# ATSAMD51P register map
Vendor: Microchip Technology Inc.; Series: SAMD51; File version: A
CPU: CM4 r0p1, little endian, MPU, FPU, 3 interrupt priority bits, 137 interrupts
Registers are 32-bit, read-write, reset 0x0 unless marked. A register's access mark holds for its fields unless they carry their own. Offsets are from the block's base; [hi:lo] are bit positions; {n}, {i} and the like mark numbered series; 'fields as' and 'values as' point back to an identical list.

## PCC — Parallel Capture Controller
Base 0x43002C00; register names take the prefix PCC_
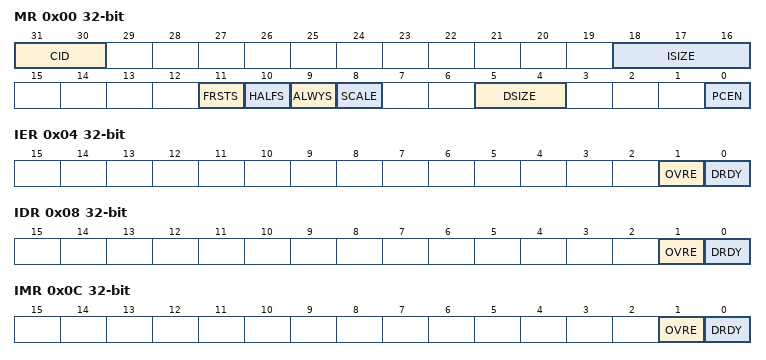
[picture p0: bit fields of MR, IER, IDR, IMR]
0x00 MR — Mode Register
  [31:30] CID — Clear If Disabled
  [18:16] ISIZE — Input Data Size
  [11] FRSTS — First sample
  [10] HALFS — Half Sampling
  [9] ALWYS — Always Sampling
  [8] SCALE — Scale data
  [5:4] DSIZE — Data size
  [0] PCEN — Parallel Capture Enable
0x04 IER wo — Interrupt Enable Register
  [1] OVRE — Overrun Error Interrupt Enable
  [0] DRDY — Data Ready Interrupt Enable
0x08 IDR wo — Interrupt Disable Register
  [1] OVRE — Overrun Error Interrupt Disable
  [0] DRDY — Data Ready Interrupt Disable
0x0C IMR ro — Interrupt Mask Register
  [1] OVRE — Overrun Error Interrupt Mask
  [0] DRDY — Data Ready Interrupt Mask
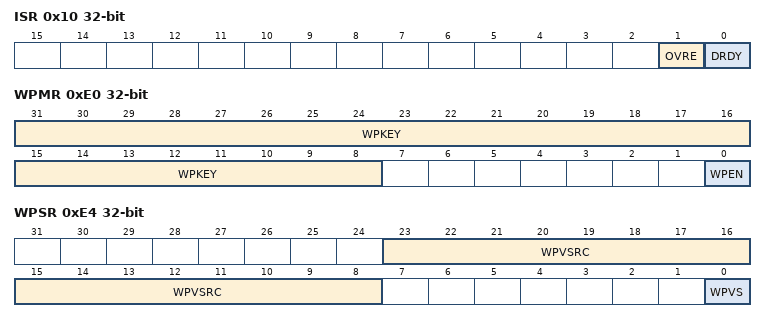
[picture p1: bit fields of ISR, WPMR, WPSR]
0x10 ISR ro — Interrupt Status Register
  [1] OVRE — Overrun Error Interrupt Status
  [0] DRDY — Data Ready Interrupt Status
0x14 RHR ro — Reception Holding Register
  [31:0] RDATA — Reception Data
0xE0 WPMR — Write Protection Mode Register
  [31:8] WPKEY — Write Protection Key
  [0] WPEN — Write Protection Enable
0xE4 WPSR ro — Write Protection Status Register
  [23:8] WPVSRC — Write Protection Violation Status
  [0] WPVS — Write Protection Violation Source

## PM — Power Manager
Base 0x40000400; register names take the prefix PM_
0x00 CTRLA 8-bit — Control A
  [2] IORET — I/O Retention
0x01 SLEEPCFG 8-bit reset 0x2 — Sleep Configuration
  [2:0] SLEEPMODE
    0=IDLE0 (CPU clock is OFF); 1=IDLE1 (AHB clock is OFF); 2=IDLE2 (APB clock are OFF); 4=STANDBY (All Clocks are OFF); 5=HIBERNATE (Backup domain is ON as well as some PDRAMs); 6=BACKUP (Only Backup domain is powered ON); 7=OFF (All power domains are powered OFF)
0x04 INTENCLR 8-bit — Interrupt Enable Clear
  [0] SLEEPRDY wo — Sleep Mode Entry Ready Enable
0x05 INTENSET 8-bit — Interrupt Enable Set
  [0] SLEEPRDY — Sleep Mode Entry Ready Enable
0x06 INTFLAG 8-bit — Interrupt Flag Status and Clear
  [0] SLEEPRDY — Sleep Mode Entry Ready
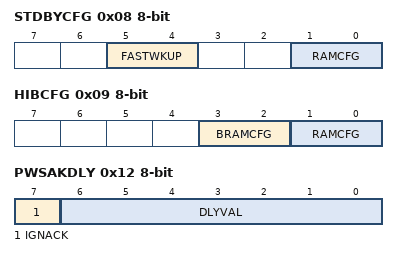
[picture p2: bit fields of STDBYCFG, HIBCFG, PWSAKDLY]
0x08 STDBYCFG 8-bit — Standby Configuration
  [5:4] FASTWKUP — Fast Wakeup
  [1:0] RAMCFG — Ram Configuration
    0=RET (All the RAMs are retained); 1=PARTIAL (Only the first 32K bytes are retained); 2=OFF (All the RAMs are OFF)
0x09 HIBCFG 8-bit — Hibernate Configuration
  [3:2] BRAMCFG — Backup Ram Configuration
  [1:0] RAMCFG — Ram Configuration
0x0A BKUPCFG 8-bit — Backup Configuration
  [1:0] BRAMCFG — Ram Configuration
0x12 PWSAKDLY 8-bit — Power Switch Acknowledge Delay
  [7] IGNACK — Ignore Acknowledge
  [6:0] DLYVAL — Delay Value

## PORT — Port Module
Base 0x41008000; register names take the prefix PORT_
{0x0+0x80*i} DIR{i} (i=0..3) — Data Direction
  [31:0] DIR — Port Data Direction
{0x4+0x80*i} DIRCLR{i} (i=0..3) — Data Direction Clear
  [31:0] DIRCLR — Port Data Direction Clear
{0x8+0x80*i} DIRSET{i} (i=0..3) — Data Direction Set
  [31:0] DIRSET — Port Data Direction Set
{0xC+0x80*i} DIRTGL{i} (i=0..3) — Data Direction Toggle
  [31:0] DIRTGL — Port Data Direction Toggle
{0x10+0x80*i} OUT{i} (i=0..3) — Data Output Value
  [31:0] OUT — PORT Data Output Value
{0x14+0x80*i} OUTCLR{i} (i=0..3) — Data Output Value Clear
  [31:0] OUTCLR — PORT Data Output Value Clear
{0x18+0x80*i} OUTSET{i} (i=0..3) — Data Output Value Set
  [31:0] OUTSET — PORT Data Output Value Set
{0x1C+0x80*i} OUTTGL{i} (i=0..3) — Data Output Value Toggle
  [31:0] OUTTGL — PORT Data Output Value Toggle
{0x20+0x80*i} IN{i} (i=0..3) ro — Data Input Value
  [31:0] IN — PORT Data Input Value
{0x24+0x80*i} CTRL{i} (i=0..3) — Control
  [31:0] SAMPLING wo — Input Sampling Mode
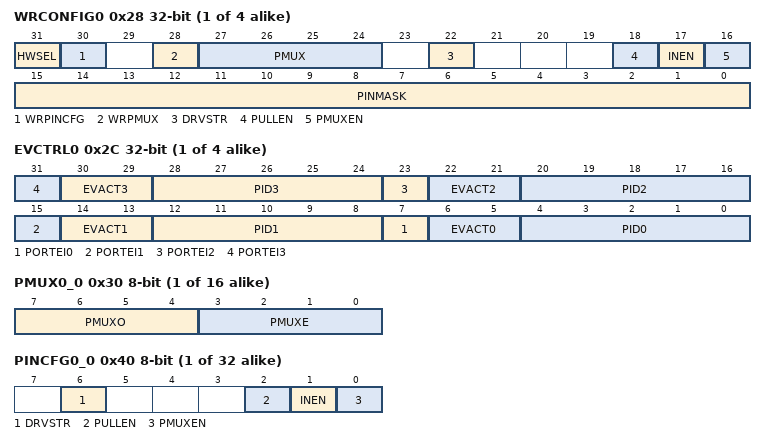
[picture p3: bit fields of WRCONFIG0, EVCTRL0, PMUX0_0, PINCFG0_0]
{0x28+0x80*i} WRCONFIG{i} (i=0..3) wo — Write Configuration
  [31] HWSEL — Half-Word Select
  [30] WRPINCFG — Write PINCFG
  [28] WRPMUX — Write PMUX
  [27:24] PMUX — Peripheral Multiplexing
  [22] DRVSTR — Output Driver Strength Selection
  [18] PULLEN — Pull Enable
  [17] INEN — Input Enable
  [16] PMUXEN — Peripheral Multiplexer Enable
  [15:0] PINMASK — Pin Mask for Multiple Pin Configuration
{0x2C+0x80*i} EVCTRL{i} (i=0..3) — Event Input Control
  [8n+7] PORTEI{n} (n=0..3) — PORT Event Input Enable {n}
  [30:29] EVACT3 — PORT Event Action 3
  [8n+4:8n] PID{n} (n=0..3) — PORT Event Pin Identifier {n}
  [22:21] EVACT2 — PORT Event Action 2
  [14:13] EVACT1 — PORT Event Action 1
  [6:5] EVACT0 — PORT Event Action 0
    0=OUT (Event output to pin); 1=SET (Set output register of pin on event); 2=CLR (Clear output register of pin on event); 3=TGL (Toggle output register of pin on event)
{0x30+i} PMUX0_{i} (i=0..15) 8-bit — Peripheral Multiplexing - Group 0
  [7:4] PMUXO — Peripheral Multiplexing for Odd-Numbered Pin
  [3:0] PMUXE — Peripheral Multiplexing for Even-Numbered Pin
{0x40+i} PINCFG0_{i} (i=0..31) 8-bit — Pin Configuration - Group 0
  [6] DRVSTR — Output Driver Strength Selection
  [2] PULLEN — Pull Enable
  [1] INEN — Input Enable
  [0] PMUXEN — Peripheral Multiplexer Enable
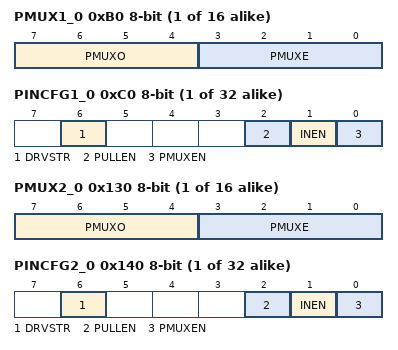
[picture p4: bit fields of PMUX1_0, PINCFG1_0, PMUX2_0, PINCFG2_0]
{0xB0+i} PMUX1_{i} (i=0..15) 8-bit — Peripheral Multiplexing - Group 1
  fields as PMUX0_0
{0xC0+i} PINCFG1_{i} (i=0..31) 8-bit — Pin Configuration - Group 1
  fields as PINCFG0_0
{0x130+i} PMUX2_{i} (i=0..15) 8-bit — Peripheral Multiplexing - Group 2
  fields as PMUX0_0
{0x140+i} PINCFG2_{i} (i=0..31) 8-bit — Pin Configuration - Group 2
  fields as PINCFG0_0
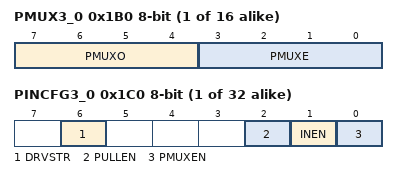
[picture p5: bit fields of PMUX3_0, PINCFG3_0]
{0x1B0+i} PMUX3_{i} (i=0..15) 8-bit — Peripheral Multiplexing - Group 3
  fields as PMUX0_0
{0x1C0+i} PINCFG3_{i} (i=0..31) 8-bit — Pin Configuration - Group 3
  fields as PINCFG0_0

## RAMECC
Base 0x41020000; register names take the prefix RAMECC_
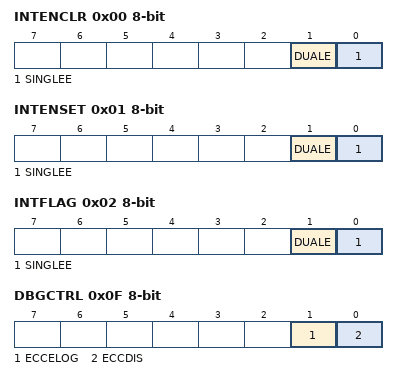
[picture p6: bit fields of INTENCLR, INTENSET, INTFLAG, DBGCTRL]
0x00 INTENCLR 8-bit — Interrupt Enable Clear
  [1] DUALE — Dual Bit ECC Error Interrupt Enable Clear
  [0] SINGLEE — Single Bit ECC Error Interrupt Enable Clear
0x01 INTENSET 8-bit — Interrupt Enable Set
  [1] DUALE — Dual Bit ECC Error Interrupt Enable Set
  [0] SINGLEE — Single Bit ECC Error Interrupt Enable Set
0x02 INTFLAG 8-bit — Interrupt Flag
  [1] DUALE — Dual Bit ECC Error Interrupt
  [0] SINGLEE — Single Bit ECC Error Interrupt
0x03 STATUS 8-bit ro
  [0] ECCDIS — ECC Disable
0x04 ERRADDR ro — Error Address
  [16:0] ERRADDR
0x0F DBGCTRL 8-bit — Debug Control
  [1] ECCELOG — ECC Error Log
  [0] ECCDIS — ECC Disable

## RSTC — Reset Controller
Base 0x40000C00; register names take the prefix RSTC_
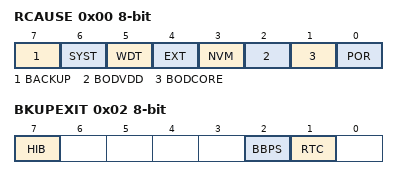
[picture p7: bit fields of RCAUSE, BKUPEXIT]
0x00 RCAUSE 8-bit ro — Reset Cause
  [7] BACKUP — Backup Reset
  [6] SYST — System Reset Request
  [5] WDT — Watchdog Reset
  [4] EXT — External Reset
  [3] NVM — NVM Reset
  [2] BODVDD — Brown Out VDD Detector Reset
  [1] BODCORE — Brown Out CORE Detector Reset
  [0] POR — Power On Reset
0x02 BKUPEXIT 8-bit ro — Backup Exit Source
  [7] HIB — Hibernate
  [2] BBPS — Battery Backup Power Switch
  [1] RTC — Real Timer Counter Interrupt

## TRNG — True Random Generator
Base 0x42002800; register names take the prefix TRNG_
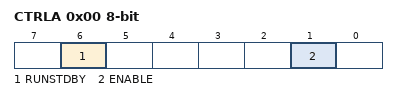
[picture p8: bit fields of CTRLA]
0x00 CTRLA 8-bit — Control A
  [6] RUNSTDBY — Run in Standby
  [1] ENABLE
0x04 EVCTRL 8-bit — Event Control
  [0] DATARDYEO — Data Ready Event Output
0x08 INTENCLR 8-bit — Interrupt Enable Clear
  [0] DATARDY — Data Ready Interrupt Enable
0x09 INTENSET 8-bit — Interrupt Enable Set
  [0] DATARDY — Data Ready Interrupt Enable
0x0A INTFLAG 8-bit — Interrupt Flag Status and Clear
  [0] DATARDY — Data Ready Interrupt Flag
0x20 DATA ro — Output Data

## WDT — Watchdog Timer
Base 0x40002000; register names take the prefix WDT_
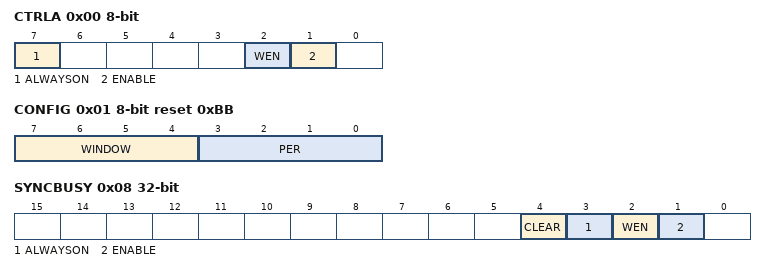
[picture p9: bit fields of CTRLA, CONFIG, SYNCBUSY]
0x00 CTRLA 8-bit — Control
  [7] ALWAYSON
  [2] WEN — Watchdog Timer Window Mode Enable
  [1] ENABLE
0x01 CONFIG 8-bit reset 0xBB — Configuration
  [7:4] WINDOW — Window Mode Time-Out Period
    0=CYC8 (8 clock cycles); 1=CYC16 (16 clock cycles); 2=CYC32 (32 clock cycles); 3=CYC64 (64 clock cycles); 4=CYC128 (128 clock cycles); 5=CYC256 (256 clock cycles); 6=CYC512 (512 clock cycles); 7=CYC1024 (1024 clock cycles); 8=CYC2048 (2048 clock cycles); 9=CYC4096 (4096 clock cycles); 10=CYC8192 (8192 clock cycles); 11=CYC16384 (16384 clock cycles)
  [3:0] PER — Time-Out Period
    values as WINDOW
0x02 EWCTRL 8-bit reset 0xB — Early Warning Interrupt Control
  [3:0] EWOFFSET — Early Warning Interrupt Time Offset
    values as CONFIG.WINDOW
0x04 INTENCLR 8-bit — Interrupt Enable Clear
  [0] EW — Early Warning Interrupt Enable
0x05 INTENSET 8-bit — Interrupt Enable Set
  [0] EW — Early Warning Interrupt Enable
0x06 INTFLAG 8-bit — Interrupt Flag Status and Clear
  [0] EW — Early Warning
0x08 SYNCBUSY ro — Synchronization Busy
  [4] CLEAR — Clear Synchronization Busy
  [3] ALWAYSON — Always-On Synchronization Busy
  [2] WEN — Window Enable Synchronization Busy
  [1] ENABLE — Enable Synchronization Busy
0x0C CLEAR 8-bit wo
  [7:0] CLEAR — Watchdog Clear
    165=KEY (Clear Key)

## Notices in the file
Copyright (c) 2018 Microchip Technology Inc.
SPDX-License-Identifier: Apache-2.0
Licensed under the Apache License, Version 2.0 (the "License");
you may not use this file except in compliance with the License.
You may obtain a copy of the License at
http://www.apache.org/licenses/LICENSE-2.0
Unless required by applicable law or agreed to in writing, software
distributed under the License is distributed on an "AS IS" BASIS,
WITHOUT WARRANTIES OR CONDITIONS OF ANY KIND, either express or implied.
See the License for the specific language governing permissions and
limitations under the License.
